# EFM32GG12B810F1024GQ100 register map
File version: 3.0.0
CPU: CM4 r0p1, little endian, MPU, FPU, 3 interrupt priority bits
Registers are 32-bit, read-write, reset 0x0 unless marked. A register's access mark holds for its fields unless they carry their own. Offsets are from the block's base; [hi:lo] are bit positions; {n}, {i} and the like mark numbered series; 'fields as' and 'values as' point back to an identical list.

## RTC
Base 0x40060000
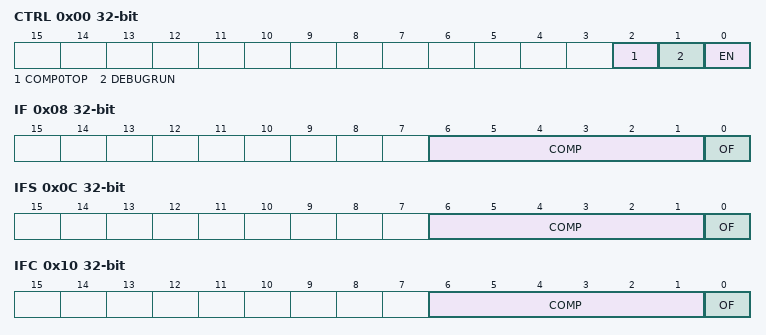
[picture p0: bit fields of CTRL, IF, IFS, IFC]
0x00 CTRL — Control Register
  [2] COMP0TOP — Compare Channel 0 is Top Value
  [1] DEBUGRUN — Debug Mode Run Enable
  [0] EN — RTC Enable
0x04 CNT — Counter Value Register
  [23:0] CNT — Counter Value
0x08 IF ro — Interrupt Flag Register
  [6:1] COMP — Compare Match X Interrupt Flag
  [0] OF — Overflow Interrupt Flag
0x0C IFS wo — Interrupt Flag Set Register
  [6:1] COMP — Set COMP Interrupt Flag
  [0] OF — Set OF Interrupt Flag
0x10 IFC wo — Interrupt Flag Clear Register
  [6:1] COMP — Clear COMP Interrupt Flag
  [0] OF — Clear OF Interrupt Flag
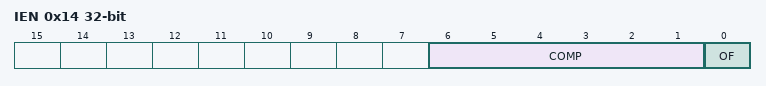
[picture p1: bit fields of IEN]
0x14 IEN — Interrupt Enable Register
  [6:1] COMP — COMP Interrupt Enable
  [0] OF — OF Interrupt Enable
0x20 COMPA_COMP — Compare Value Register X
  [23:0] COMP — Compare Value
0x24 COMPB_COMP — Compare Value Register X
  [23:0] COMP — Compare Value
0x28 COMPC_COMP — Compare Value Register X
  [23:0] COMP — Compare Value
0x2C COMPD_COMP — Compare Value Register X
  [23:0] COMP — Compare Value
0x30 COMPE_COMP — Compare Value Register X
  [23:0] COMP — Compare Value
0x34 COMPF_COMP — Compare Value Register X
  [23:0] COMP — Compare Value

## WDOG0
Base 0x40052000
Same registers: WDOG1 0x40052400
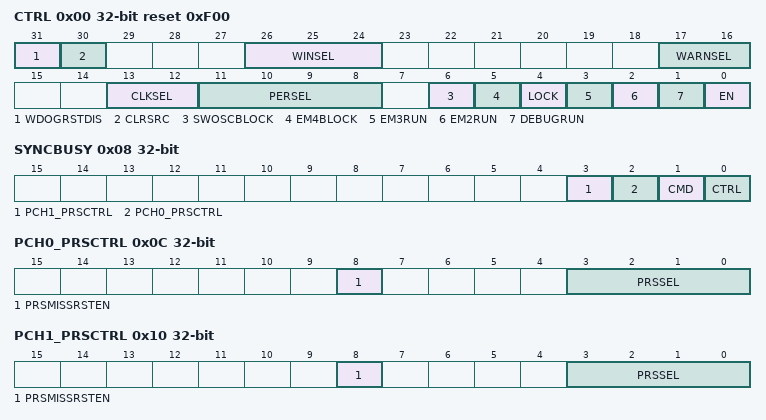
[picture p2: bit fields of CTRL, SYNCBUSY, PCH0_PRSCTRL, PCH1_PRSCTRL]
0x00 CTRL reset 0xF00 — Control Register
  [31] WDOGRSTDIS — Watchdog Reset Disable
  [30] CLRSRC — Watchdog Clear Source
  [26:24] WINSEL — Watchdog Illegal Window Select
  [17:16] WARNSEL — Watchdog Timeout Period Select
  [13:12] CLKSEL — Watchdog Clock Select
    0=ULFRCO; 1=LFRCO; 2=LFXO; 3=HFCORECLK
  [11:8] PERSEL — Watchdog Timeout Period Select
  [6] SWOSCBLOCK — Software Oscillator Disable Block
  [5] EM4BLOCK — Energy Mode 4 Block
  [4] LOCK — Configuration Lock
  [3] EM3RUN — Energy Mode 3 Run Enable
  [2] EM2RUN — Energy Mode 2 Run Enable
  [1] DEBUGRUN — Debug Mode Run Enable
  [0] EN — Watchdog Timer Enable
0x04 CMD wo — Command Register
  [0] CLEAR — Watchdog Timer Clear
0x08 SYNCBUSY ro — Synchronization Busy Register
  [3] PCH1_PRSCTRL — PCH1_PRSCTRL Register Busy
  [2] PCH0_PRSCTRL — PCH0_PRSCTRL Register Busy
  [1] CMD — CMD Register Busy
  [0] CTRL — CTRL Register Busy
0x0C PCH0_PRSCTRL — PRS Control Register
  [8] PRSMISSRSTEN — PRS Missing Event Will Trigger a Watchdog Reset
  [3:0] PRSSEL — PRS Channel PRS Select
    {v}=PRSCH{v} (PRS Channel {v} selected as input) (v=0..15)
0x10 PCH1_PRSCTRL — PRS Control Register
  fields as PCH0_PRSCTRL
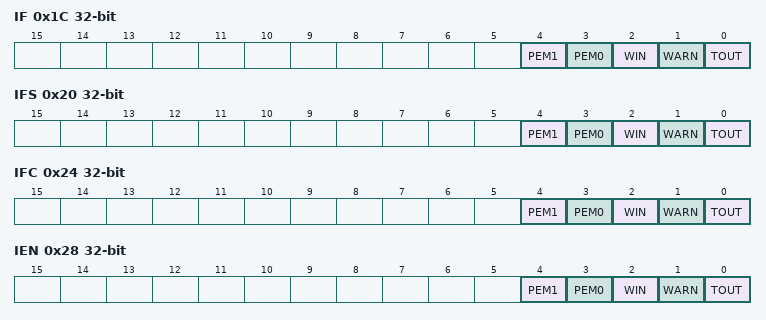
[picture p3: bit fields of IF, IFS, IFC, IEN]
0x1C IF ro — Watchdog Interrupt Flags
  [4] PEM1 — PRS Channel One Event Missing Interrupt Flag
  [3] PEM0 — PRS Channel Zero Event Missing Interrupt Flag
  [2] WIN — WDOG Window Interrupt Flag
  [1] WARN — WDOG Warning Timeout Interrupt Flag
  [0] TOUT — WDOG Timeout Interrupt Flag
0x20 IFS wo — Interrupt Flag Set Register
  [4] PEM1 — Set PEM1 Interrupt Flag
  [3] PEM0 — Set PEM0 Interrupt Flag
  [2] WIN — Set WIN Interrupt Flag
  [1] WARN — Set WARN Interrupt Flag
  [0] TOUT — Set TOUT Interrupt Flag
0x24 IFC wo — Interrupt Flag Clear Register
  [4] PEM1 — Clear PEM1 Interrupt Flag
  [3] PEM0 — Clear PEM0 Interrupt Flag
  [2] WIN — Clear WIN Interrupt Flag
  [1] WARN — Clear WARN Interrupt Flag
  [0] TOUT — Clear TOUT Interrupt Flag
0x28 IEN — Interrupt Enable Register
  [4] PEM1 — PEM1 Interrupt Enable
  [3] PEM0 — PEM0 Interrupt Enable
  [2] WIN — WIN Interrupt Enable
  [1] WARN — WARN Interrupt Enable
  [0] TOUT — TOUT Interrupt Enable

## TRNG0
Base 0x4001D000
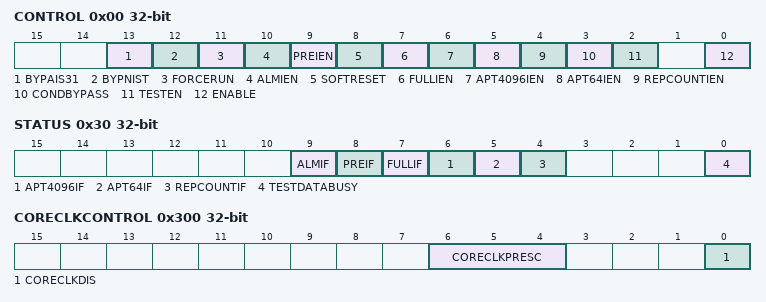
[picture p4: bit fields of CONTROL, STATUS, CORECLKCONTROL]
0x00 CONTROL — Main Control Register
  [13] BYPAIS31 — AIS31 Start-up Test Bypass.
  [12] BYPNIST — NIST Start-up Test Bypass.
  [11] FORCERUN — Oscillator Force Run
  [10] ALMIEN — Interrupt enable for AIS31 noise alarm
  [9] PREIEN — Interrupt enable for AIS31 preliminary noise alarm
  [8] SOFTRESET — Software Reset
  [7] FULLIEN — Interrupt Enable for FIFO Full
  [6] APT4096IEN — Interrupt Enable for Adaptive Proportion Test Failure (4096-sample Window)
  [5] APT64IEN — Interrupt Enable for Adaptive Proportion Test Failure (64-sample Window)
  [4] REPCOUNTIEN — Interrupt Enable for Repetition Count Test Failure
  [3] CONDBYPASS — Conditioning Bypass
  [2] TESTEN — Test Enable
  [0] ENABLE — TRNG Module Enable
0x04 FIFOLEVEL ro read-has-side-effects
  [31:0] VALUE — FIFO Level
0x0C FIFODEPTH ro reset 0x40
  [31:0] VALUE — FIFO Depth.
{0x10+4i} KEY{i} (i=0..3) — Key Register {i}
  [31:0] VALUE — Key {i}
0x20 TESTDATA
  [31:0] VALUE — Test data input to conditioning function or to the continuous tests
0x30 STATUS
  [9] ALMIF ro — AIS31 Noise Alarm interrupt status
  [8] PREIF — AIS31 Preliminary Noise Alarm interrupt status
  [7] FULLIF ro — FIFO Full Interrupt Status
  [6] APT4096IF ro — Adaptive Proportion test failure (4096-sample window) interrupt status
  [5] APT64IF ro — Adaptive Proportion test failure (64-sample window) interrupt status
  [4] REPCOUNTIF ro — Repetition Count Test Interrupt Status
  [0] TESTDATABUSY ro
0x34 INITWAITVAL reset 0x3FF — Initial Wait Counter
  [9:0] VALUE — Wait counter value
0x100 FIFO ro read-has-side-effects — FIFO Data
  [31:0] VALUE — FIFO Read Data
0x300 CORECLKCONTROL — Core Clock Control Register
  [6:4] CORECLKPRESC — Clock division factor of CORECLKPRESC+1
  [0] CORECLKDIS — Core Clock Disable
